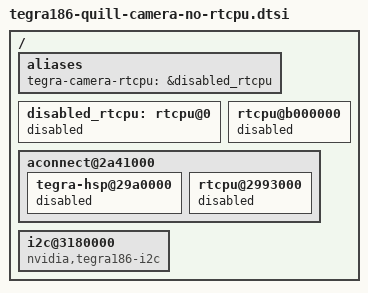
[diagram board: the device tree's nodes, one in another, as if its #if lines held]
/*
 * tegra186-quill-camera-no-rtcpu.dtsi: Quill sans Camera RTCPU
 *
 * Copyright (c) 2016, NVIDIA CORPORATION.  All rights reserved.
 *
 * This program is free software; you can redistribute it and/or modify
 * it under the terms of the GNU General Public License as published by
 * the Free Software Foundation; version 2 of the License.
 *
 * This program is distributed in the hope that it will be useful, but WITHOUT
 * ANY WARRANTY; without even the implied warranty of MERCHANTABILITY or
 * FITNESS FOR A PARTICULAR PURPOSE.  See the GNU General Public License for
 * more details.
 */

/ {
	aliases {
		tegra-camera-rtcpu = &disabled_rtcpu;
	};

	disabled_rtcpu: rtcpu@0 {
		status = "disabled";
	};

	/* SCE HSP is not disabled, it can be used by Safety FW */

	rtcpu@b000000 {	/* Do not use SCE as camera-rtcpu */
		status = "disabled";
	};

#if TEGRA_AUDIO_BUS_DT_VERSION >= DT_VERSION_2
	aconnect@2a41000 {
#endif
	tegra-hsp@29a0000 { /* Do not use APE HSP */
		status = "disabled";
	};

	rtcpu@2993000 {	/* Do not use APE as camera-rtcpu */
		status = "disabled";
	};

#if TEGRA_AUDIO_BUS_DT_VERSION >= DT_VERSION_2
	};
#endif

	i2c@3180000 { /* Do not use RTCPU I2C driver */
		compatible = "nvidia,tegra186-i2c";
	};
};
